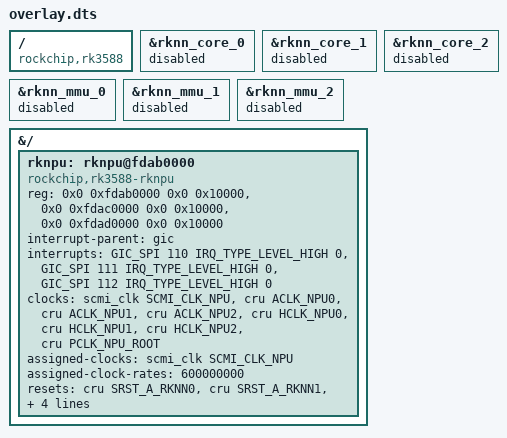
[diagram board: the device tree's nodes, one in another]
/dts-v1/;
/plugin/;

#include <dt-bindings/clock/rockchip,rk3588-cru.h>
#include <dt-bindings/reset/rockchip,rk3588-cru.h>
#include <dt-bindings/power/rk3588-power.h>
#include <dt-bindings/interrupt-controller/arm-gic.h>
#include <dt-bindings/interrupt-controller/irq.h>

/*
 * Rockchip RKNPU (vendor v0.9.8 driver) for RK3588 on mainline kernels.
 *
 * NON-IOMMU MODE, DELIBERATELY. The vendor node carries NO iommus
 * property, so the driver runs with physical DMA addresses
 * ("using non-iommu mode" in dmesg).
 *
 * Why: the RK3588 NPU IOMMU is one logical device with four register
 * windows spanning three cores' clock domains (the BSP gives it six
 * gates: aclk0-2/iface0-2). The mainline rockchip-iommu driver
 * bulk-gets exactly two clocks ("aclk"/"iface"), so a merged
 * four-window node aborts on the windows whose gates it cannot
 * enable (observed: synchronous external abort in
 * rk_iommu_enable_stall during supplier resume), and three separate
 * per-core nodes cannot work either - the vendor driver maps through
 * ONE domain, and mainline's generic_single_device_group/of_xlate
 * attach that domain to only the LAST xlate's MMU (silent corruption
 * on the other two cores). Per-window clock support in the mainline
 * driver is the proper fix; until then, non-IOMMU mode is the
 * driver's own supported fallback. Trade-off: no DMA isolation for
 * the NPU - acceptable for a single-tenant ML appliance.
 *
 * The mainline rocket (accel) driver owns the same MMIO when its
 * cores are enabled, so they (and their per-core IOMMUs) are
 * switched off below.
 */

/ {
	compatible = "rockchip,rk3588";
};

&rknn_core_0 {
	status = "disabled";
};

&rknn_core_1 {
	status = "disabled";
};

&rknn_core_2 {
	status = "disabled";
};

&rknn_mmu_0 {
	status = "disabled";
};

&rknn_mmu_1 {
	status = "disabled";
};

&rknn_mmu_2 {
	status = "disabled";
};

&{/} {
	rknpu: rknpu@fdab0000 {
		compatible = "rockchip,rk3588-rknpu";
		reg = <0x0 0xfdab0000 0x0 0x10000>,
		      <0x0 0xfdac0000 0x0 0x10000>,
		      <0x0 0xfdad0000 0x0 0x10000>;
		interrupt-parent = <&gic>;
		interrupts = <GIC_SPI 110 IRQ_TYPE_LEVEL_HIGH 0>,
			     <GIC_SPI 111 IRQ_TYPE_LEVEL_HIGH 0>,
			     <GIC_SPI 112 IRQ_TYPE_LEVEL_HIGH 0>;
		interrupt-names = "npu0_irq", "npu1_irq", "npu2_irq";
		clocks = <&scmi_clk SCMI_CLK_NPU>, <&cru ACLK_NPU0>,
			 <&cru ACLK_NPU1>, <&cru ACLK_NPU2>,
			 <&cru HCLK_NPU0>, <&cru HCLK_NPU1>,
			 <&cru HCLK_NPU2>, <&cru PCLK_NPU_ROOT>;
		clock-names = "clk_npu", "aclk0",
			      "aclk1", "aclk2",
			      "hclk0", "hclk1",
			      "hclk2", "pclk";
		assigned-clocks = <&scmi_clk SCMI_CLK_NPU>;
		/* BSP default is 200 MHz; 600 MHz is the practical fixed
		 * rate used for RK3588 NPU bring-up. HARDWARE REVIEW: this
		 * sets rate only - nothing sets the NPU rail voltage, so
		 * confirm stability on the board before raising it. */
		assigned-clock-rates = <600000000>;
		resets = <&cru SRST_A_RKNN0>, <&cru SRST_A_RKNN1>,
			 <&cru SRST_A_RKNN2>,
			 <&cru SRST_H_RKNN0>, <&cru SRST_H_RKNN1>,
			 <&cru SRST_H_RKNN2>;
		reset-names = "srst_a0", "srst_a1", "srst_a2",
			      "srst_h0", "srst_h1", "srst_h2";
		power-domains = <&power RK3588_PD_NPUTOP>,
				<&power RK3588_PD_NPU1>,
				<&power RK3588_PD_NPU2>;
		power-domain-names = "npu0", "npu1", "npu2";
		status = "okay";
	};
};
